# ATSAMC20N18A register map
Vendor: Microchip Technology; Series: SAMC20; File version: 0
CPU: CM0+ r0p0, little endian, MPU, VTOR, 2 interrupt priority bits, 31 interrupts
Registers are 32-bit, read-write, reset 0x0 unless marked. A register's access mark holds for its fields unless they carry their own. Offsets are from the block's base; [hi:lo] are bit positions; 'fields as' and 'values as' point back to an identical list.

## RSTC — Reset Controller
Base 0x40000C00
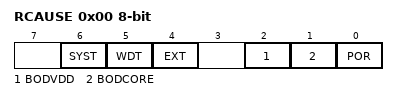
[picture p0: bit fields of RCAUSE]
0x00 RCAUSE 8-bit ro — Reset Cause
  [6] SYST — System Reset Request
  [5] WDT — Watchdog Reset
  [4] EXT — External Reset
  [2] BODVDD — Brown Out VDD Detector Reset
  [1] BODCORE — Brown Out CORE Detector Reset
  [0] POR — Power On Reset

## SUPC — Supply Controller
Base 0x40001800
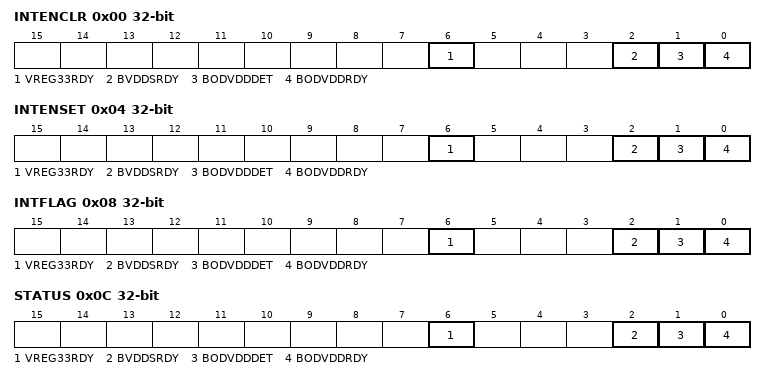
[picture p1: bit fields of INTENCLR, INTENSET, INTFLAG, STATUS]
0x00 INTENCLR — Interrupt Enable Clear
  [6] VREG33RDY — VREG33 Ready
  [2] BVDDSRDY — BODVDD Synchronization Ready
  [1] BODVDDDET — BODVDD Detection
  [0] BODVDDRDY — BODVDD Ready
0x04 INTENSET — Interrupt Enable Set
  fields as INTENCLR
0x08 INTFLAG — Interrupt Flag Status and Clear
  fields as INTENCLR
0x0C STATUS ro — Power and Clocks Status
  fields as INTENCLR
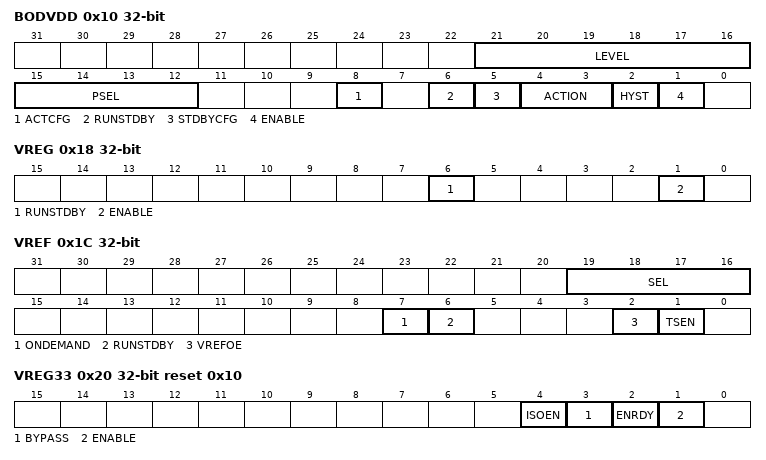
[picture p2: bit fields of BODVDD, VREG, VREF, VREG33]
0x10 BODVDD — BODVDD Control
  [21:16] LEVEL — Threshold Level for VDD
  [15:12] PSEL — Prescaler Select
    0=DIV2 (Divide clock by 2); 1=DIV4 (Divide clock by 4); 2=DIV8 (Divide clock by 8); 3=DIV16 (Divide clock by 16); 4=DIV32 (Divide clock by 32); 5=DIV64 (Divide clock by 64); 6=DIV128 (Divide clock by 128); 7=DIV256 (Divide clock by 256); 8=DIV512 (Divide clock by 512); 9=DIV1024 (Divide clock by 1024); 10=DIV2048 (Divide clock by 2048); 11=DIV4096 (Divide clock by 4096); 12=DIV8192 (Divide clock by 8192); 13=DIV16384 (Divide clock by 16384); 14=DIV32768 (Divide clock by 32768); 15=DIV65536 (Divide clock by 65536)
  [8] ACTCFG — Configuration in Active mode
  [6] RUNSTDBY — Run during Standby
  [5] STDBYCFG — Configuration in Standby mode
  [4:3] ACTION — Action when Threshold Crossed
    0=NONE (No action); 1=RESET (The BODVDD generates a reset); 2=INT (The BODVDD generates an interrupt)
  [2] HYST — Hysteresis Enable
  [1] ENABLE
0x18 VREG — VREG Control
  [6] RUNSTDBY — Run during Standby
  [1] ENABLE
0x1C VREF — VREF Control
  [19:16] SEL — Voltage Reference Selection
    0=1V024 (1.024V voltage reference typical value); 2=2V048 (2.048V voltage reference typical value); 3=4V096 (4.096V voltage reference typical value)
  [7] ONDEMAND — On Demand Control
  [6] RUNSTDBY — Run during Standby
  [2] VREFOE — Voltage Reference Output Enable
  [1] TSEN — Temperature Sensor Output Enable
0x20 VREG33 reset 0x10 — VREG33 Control
  [4] ISOEN — Isolation Enable
  [3] BYPASS — VREG33 Bypass
  [2] ENRDY — VREG33 Ready Enable
  [1] ENABLE — VREG33 Enable

## WDT — Watchdog Timer
Base 0x40002000
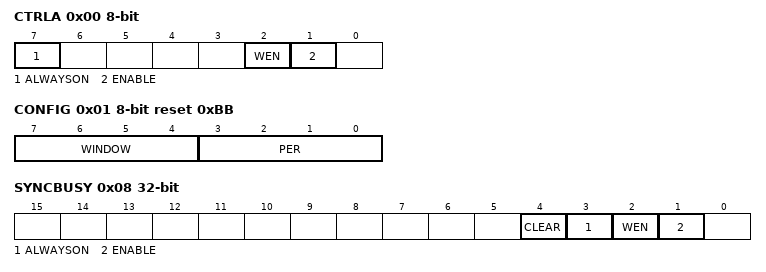
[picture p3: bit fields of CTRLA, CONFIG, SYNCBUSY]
0x00 CTRLA 8-bit — Control
  [7] ALWAYSON
  [2] WEN — Watchdog Timer Window Mode Enable
  [1] ENABLE
0x01 CONFIG 8-bit reset 0xBB — Configuration
  [7:4] WINDOW — Window Mode Time-Out Period
    0=CYC8 (8 clock cycles); 1=CYC16 (16 clock cycles); 2=CYC32 (32 clock cycles); 3=CYC64 (64 clock cycles); 4=CYC128 (128 clock cycles); 5=CYC256 (256 clock cycles); 6=CYC512 (512 clock cycles); 7=CYC1024 (1024 clock cycles); 8=CYC2048 (2048 clock cycles); 9=CYC4096 (4096 clock cycles); 10=CYC8192 (8192 clock cycles); 11=CYC16384 (16384 clock cycles)
  [3:0] PER — Time-Out Period
    values as WINDOW
0x02 EWCTRL 8-bit reset 0xB — Early Warning Interrupt Control
  [3:0] EWOFFSET — Early Warning Interrupt Time Offset
    values as CONFIG.WINDOW
0x04 INTENCLR 8-bit — Interrupt Enable Clear
  [0] EW — Early Warning Interrupt Enable
0x05 INTENSET 8-bit — Interrupt Enable Set
  [0] EW — Early Warning Interrupt Enable
0x06 INTFLAG 8-bit — Interrupt Flag Status and Clear
  [0] EW — Early Warning
0x08 SYNCBUSY ro — Synchronization Busy
  [4] CLEAR — Clear Busy
  [3] ALWAYSON — Always-On Busy
  [2] WEN — Window Enable Busy
  [1] ENABLE — Enable Busy
0x0C CLEAR 8-bit wo
  [7:0] CLEAR — Watchdog Clear
    165=KEY (Clear Key)

## MPU — Memory Protection Unit
Base 0xE000ED90
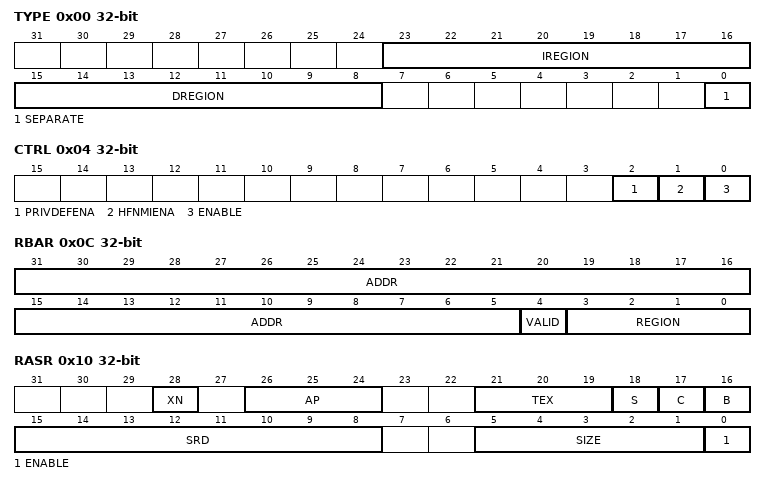
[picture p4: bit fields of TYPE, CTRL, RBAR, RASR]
0x00 TYPE ro — MPU Type Register
  [23:16] IREGION — Number of Instruction Regions
  [15:8] DREGION — Number of Data Regions
  [0] SEPARATE — Separate instruction and Data Memory MapsRegions
0x04 CTRL — MPU Control Register
  [2] PRIVDEFENA — Enables privileged software access to default memory map
  [1] HFNMIENA — Enable Hard Fault and NMI handlers
  [0] ENABLE — MPU Enable
0x08 RNR — MPU Region Number Register
  [7:0] REGION — Region referenced by RBAR and RASR
0x0C RBAR — MPU Region Base Address Register
  [31:5] ADDR — Region base address
  [4] VALID — Region number valid
  [3:0] REGION — Region number
0x10 RASR — MPU Region Attribute and Size Register
  [28] XN — Execute Never Attribute
  [26:24] AP — Access Permission
  [21:19] TEX — TEX bit
  [18] S — Shareable bit
  [17] C — Cacheable bit
  [16] B — Bufferable bit
  [15:8] SRD — Sub-region disable
  [5:1] SIZE — Region Size
  [0] ENABLE — Region Enable

## Notices in the file
Copyright (c) 2025 Microchip Technology Inc.
SPDX-License-Identifier: Apache-2.0
Licensed under the Apache License, Version 2.0 (the "License");
you may not use this file except in compliance with the License.
You may obtain a copy of the License at
http://www.apache.org/licenses/LICENSE-2.0
Unless required by applicable law or agreed to in writing, software
distributed under the License is distributed on an "AS IS" BASIS,
WITHOUT WARRANTIES OR CONDITIONS OF ANY KIND, either express or implied.
See the License for the specific language governing permissions and
limitations under the License.
